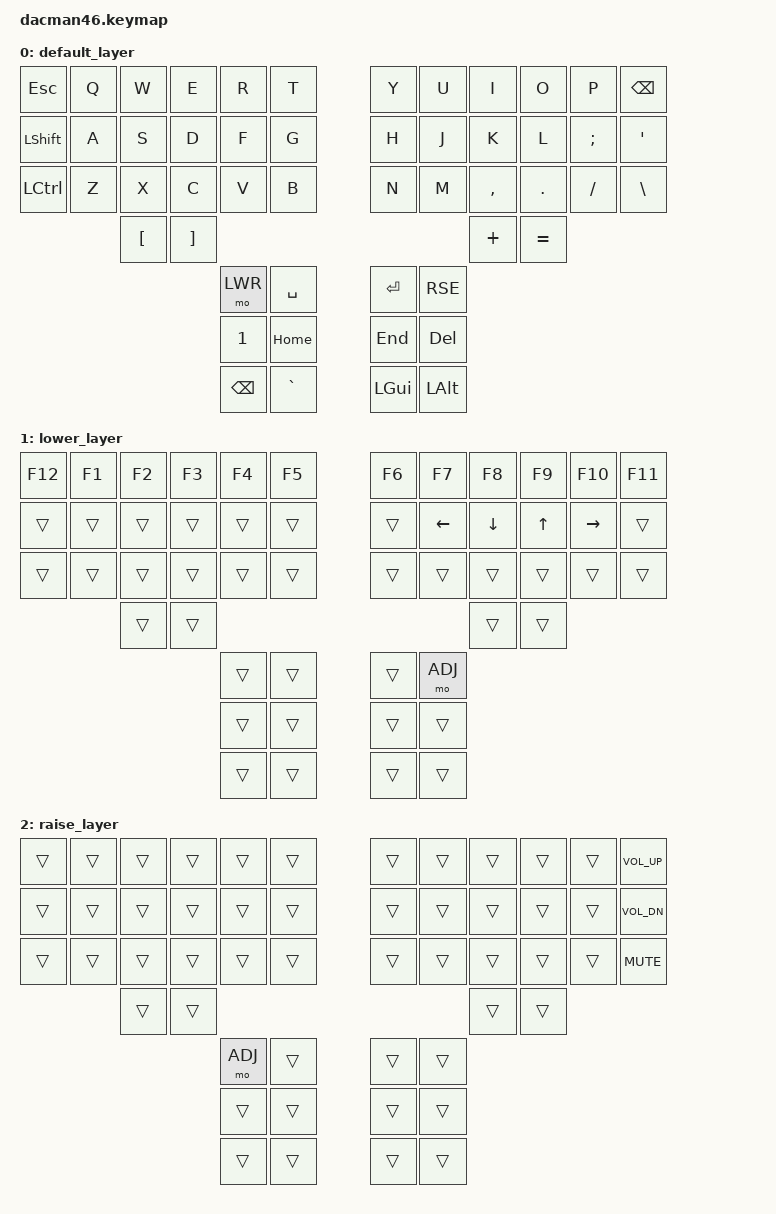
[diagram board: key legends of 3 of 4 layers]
/*
 * Copyright (c) 2020 The ZMK Contributors
 *
 * SPDX-License-Identifier: MIT
 */

#include <behaviors.dtsi>
#include <dt-bindings/zmk/keys.h>
#include <dt-bindings/zmk/bt.h>
#include <dt-bindings/zmk/outputs.h>

#define LWR 1
#define RSE 2
#define ADJ 3

/ {
    keymap {
        compatible = "zmk,keymap";

        default_layer {
            bindings = <
                &kp ESC   &kp Q  &kp W  &kp E  &kp R  &kp T               &kp Y  &kp U  &kp I     &kp O   &kp P    &kp BSPC
                &kp LSHFT &kp A  &kp S  &kp D  &kp F  &kp G               &kp H  &kp J  &kp K     &kp L   &kp SEMI &kp SQT
                &kp LCTRL &kp Z  &kp X  &kp C  &kp V  &kp B               &kp N  &kp M  &kp COMMA &kp DOT &kp FSLH &kp BSLH
                                 &kp LBKT &kp RBKT                                      &kp PLUS &kp EQUAL
                                            &mo LWR  &kp SPACE            &kp RET  &kp RSE
                                            &kp N1   &kp HOME             &kp END  &kp DEL
                                            &kp BSPC &kp GRAVE            &kp LGUI &kp LALT
            >;
        };

        lower_layer {
            bindings = <
                &kp F12 &kp F1 &kp F2 &kp F3 &kp F4 &kp F5                &kp F6 &kp F7   &kp F8   &kp F9 &kp F10   &kp F11
                &trans  &trans &trans &trans &trans &trans                &trans &kp LEFT &kp DOWN &kp UP &kp RIGHT &trans
                &trans  &trans &trans &trans &trans &trans                &trans &trans   &trans   &trans &trans    &trans
                               &trans &trans                                              &trans &trans
                                             &trans &trans                &trans &mo ADJ
                                             &trans &trans                &trans &trans
                                             &trans &trans                &trans &trans
            >;
        };

        raise_layer {
            bindings = <
                &trans  &trans &trans &trans &trans &trans                &trans &trans &trans &trans &trans &kp K_VOL_UP
                &trans  &trans &trans &trans &trans &trans                &trans &trans &trans &trans &trans &kp K_VOL_DN
                &trans  &trans &trans &trans &trans &trans                &trans &trans &trans &trans &trans &kp K_MUTE
                               &trans &trans                                            &trans &trans
                                             &mo ADJ &trans               &trans &trans
                                             &trans  &trans               &trans &trans
                                             &trans  &trans               &trans &trans
            >;
        };

        adjust_layer {
            bindings = <
                &none &bt BT_SEL 0 &out OUT_BLE &none &none  &none            &none &none &none &none &none &none
                &none &bt BT_SEL 1 &out OUT_USB &none &none  &none            &none &none &none &none &none &none
                &none &bt BT_SEL 2 &none        &none &none  &none            &none &none &none &none &none &none
                &none &bt BT_SEL 3 &bt BT_CLR   &none &none  &none            &none &none &none &none &none &none
                                   &none        &none                                     &none &none
                                                      &none &none             &none &none
                                                      &none &none             &none &none
                                                      &none &none             &none &none
            >;
        };
    };
};
